# ESP8266 register map
File version: 1.0
CPU: Xtensa LX106 1, little endian, no MPU, FPU, 3 interrupt priority bits
Registers are 32-bit, read-write, reset 0x0 unless marked. A register's access mark holds for its fields unless they carry their own. Offsets are from the block's base; [hi:lo] are bit positions; 'fields as' and 'values as' point back to an identical list.

## UART0
Base 0x60000000
0x00 UART_FIFO access not given — UART FIFO,length 128
  [7:0] rxfifo_rd_byte ro — R/W share the same address
  [7:0] rxfifo_write_byte — R/W share the same address
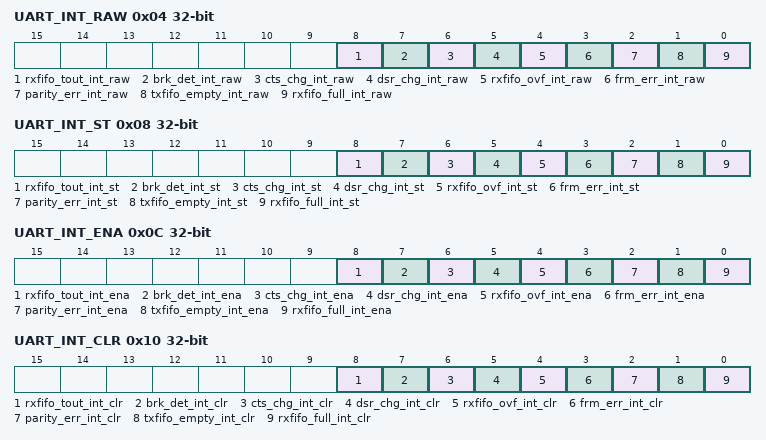
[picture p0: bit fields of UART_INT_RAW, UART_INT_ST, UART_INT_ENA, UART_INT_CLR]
0x04 UART_INT_RAW ro — UART INTERRUPT RAW STATE
  [8] rxfifo_tout_int_raw — The interrupt raw bit for Rx time-out interrupt(depands on theUART_RX_TOUT_THRHD)
  [7] brk_det_int_raw — The interrupt raw bit for Rx byte start error
  [6] cts_chg_int_raw — The interrupt raw bit for CTS changing level
  [5] dsr_chg_int_raw — The interrupt raw bit for DSR changing level
  [4] rxfifo_ovf_int_raw — The interrupt raw bit for rx fifo overflow
  [3] frm_err_int_raw — The interrupt raw bit for other rx error
  [2] parity_err_int_raw — The interrupt raw bit for parity check error
  [1] txfifo_empty_int_raw — The interrupt raw bit for tx fifo empty interrupt(depands onUART_TXFIFO_EMPTY_THRHD bits)
  [0] rxfifo_full_int_raw — The interrupt raw bit for rx fifo full interrupt(depands onUART_RXFIFO_FULL_THRHD bits)
0x08 UART_INT_ST ro — UART INTERRUPT STATEREGISTERUART_INT_RAW&UART_INT_ENA
  [8] rxfifo_tout_int_st — The interrupt state bit for Rx time-out event
  [7] brk_det_int_st — The interrupt state bit for rx byte start error
  [6] cts_chg_int_st — The interrupt state bit for CTS changing level
  [5] dsr_chg_int_st — The interrupt state bit for DSR changing level
  [4] rxfifo_ovf_int_st — The interrupt state bit for RX fifo overflow
  [3] frm_err_int_st — The interrupt state for other rx error
  [2] parity_err_int_st — The interrupt state bit for rx parity error
  [1] txfifo_empty_int_st — The interrupt state bit for TX fifo empty
  [0] rxfifo_full_int_st — The interrupt state bit for RX fifo full event
0x0C UART_INT_ENA — UART INTERRUPT ENABLE REGISTER
  [8] rxfifo_tout_int_ena — The interrupt enable bit for rx time-out interrupt
  [7] brk_det_int_ena — The interrupt enable bit for rx byte start error
  [6] cts_chg_int_ena — The interrupt enable bit for CTS changing level
  [5] dsr_chg_int_ena — The interrupt enable bit for DSR changing level
  [4] rxfifo_ovf_int_ena — The interrupt enable bit for rx fifo overflow
  [3] frm_err_int_ena — The interrupt enable bit for other rx error
  [2] parity_err_int_ena — The interrupt enable bit for parity error
  [1] txfifo_empty_int_ena — The interrupt enable bit for tx fifo empty event
  [0] rxfifo_full_int_ena — The interrupt enable bit for rx fifo full event
0x10 UART_INT_CLR wo — UART INTERRUPT CLEAR REGISTER
  [8] rxfifo_tout_int_clr — Set this bit to clear the rx time-out interrupt
  [7] brk_det_int_clr — Set this bit to clear the rx byte start interrupt
  [6] cts_chg_int_clr — Set this bit to clear the CTS changing interrupt
  [5] dsr_chg_int_clr — Set this bit to clear the DSR changing interrupt
  [4] rxfifo_ovf_int_clr — Set this bit to clear the rx fifo over-flow interrupt
  [3] frm_err_int_clr — Set this bit to clear other rx error interrupt
  [2] parity_err_int_clr — Set this bit to clear the parity error interrupt
  [1] txfifo_empty_int_clr — Set this bit to clear the tx fifo empty interrupt
  [0] rxfifo_full_int_clr — Set this bit to clear the rx fifo full interrupt
0x14 UART_CLKDIV
  [19:0] uart_clkdiv — BAUDRATE = UART_CLK_FREQ / UART_CLKDIV
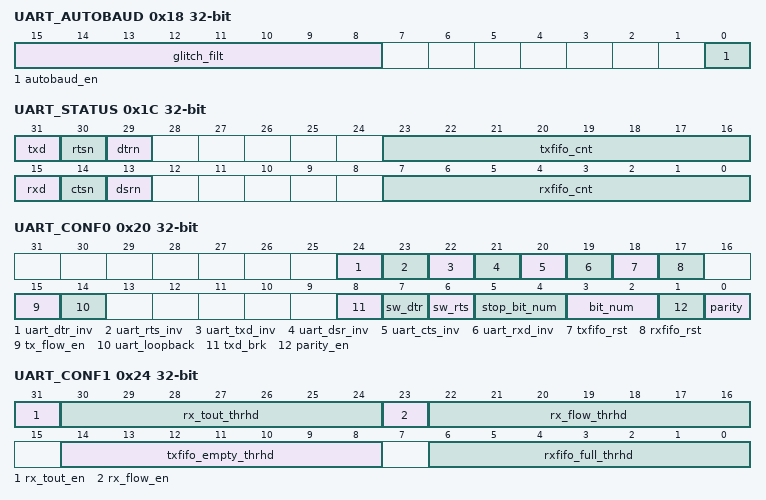
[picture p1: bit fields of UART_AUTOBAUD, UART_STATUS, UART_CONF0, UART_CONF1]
0x18 UART_AUTOBAUD — UART BAUDRATE DETECT REGISTER
  [15:8] glitch_filt
  [0] autobaud_en — Set this bit to enable baudrate detect
0x1C UART_STATUS ro
  [31] txd — The level of the uart txd pin
  [30] rtsn — The level of uart rts pin
  [29] dtrn — The level of uart dtr pin
  [23:16] txfifo_cnt — Number of data in UART TX fifo
  [15] rxd — The level of uart rxd pin
  [14] ctsn — The level of uart cts pin
  [13] dsrn — The level of uart dsr pin
  [7:0] rxfifo_cnt — Number of data in uart rx fifo
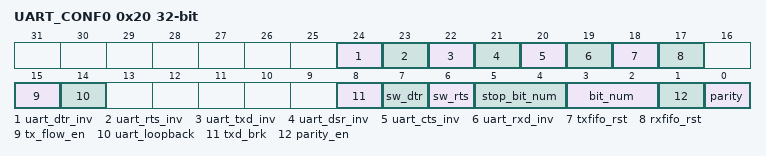
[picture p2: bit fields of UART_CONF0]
0x20 UART_CONF0 — UART CONFIG0(UART0 and UART1)
  [24] uart_dtr_inv — Set this bit to inverse uart dtr level
  [23] uart_rts_inv — Set this bit to inverse uart rts level
  [22] uart_txd_inv — Set this bit to inverse uart txd level
  [21] uart_dsr_inv — Set this bit to inverse uart dsr level
  [20] uart_cts_inv — Set this bit to inverse uart cts level
  [19] uart_rxd_inv — Set this bit to inverse uart rxd level
  [18] txfifo_rst — Set this bit to reset uart tx fifo
  [17] rxfifo_rst — Set this bit to reset uart rx fifo
  [15] tx_flow_en — Set this bit to enable uart tx hardware flow control
  [14] uart_loopback — Set this bit to enable uart loopback test mode
  [8] txd_brk — RESERVED, DO NOT CHANGE THIS BIT
  [7] sw_dtr
  [6] sw_rts
  [5:4] stop_bit_num — Set stop bit: 1:1bit 2:1.5bits 3:2bits
  [3:2] bit_num — Set bit num: 0:5bits 1:6bits 2:7bits 3:8bits
  [1] parity_en — Set this bit to enable uart parity check
  [0] parity — Set parity check: 0:even 1:odd, UART CONFIG1
0x24 UART_CONF1 — Set this bit to enable rx time-out function
  [31] rx_tout_en — Set this bit to enable rx time-out function
  [30:24] rx_tout_thrhd — Config bits for rx time-out threshold,uint: byte,0-127
  [23] rx_flow_en — Set this bit to enable rx hardware flow control
  [22:16] rx_flow_thrhd — The config bits for rx flow control threshold,0-127
  [14:8] txfifo_empty_thrhd — The config bits for tx fifo empty threshold,0-127
  [6:0] rxfifo_full_thrhd — The config bits for rx fifo full threshold,0-127
0x28 UART_LOWPULSE ro
  [19:0] lowpulse_min_cnt — used in baudrate detect
0x2C UART_HIGHPULSE ro
  [19:0] highpulse_min_cnt — used in baudrate detect
0x30 UART_RXD_CNT ro
  [9:0] rxd_edge_cnt — used in baudrate detect
0x78 UART_DATE — UART HW INFO
0x7C UART_ID

## UART1
Base 0x60000F00
Registers as UART0; these are added or differ:
0x20 UART_CONF0 — UART CONFIG0(UART0 and UART1)
  fields as UART0.UART_CONF0
